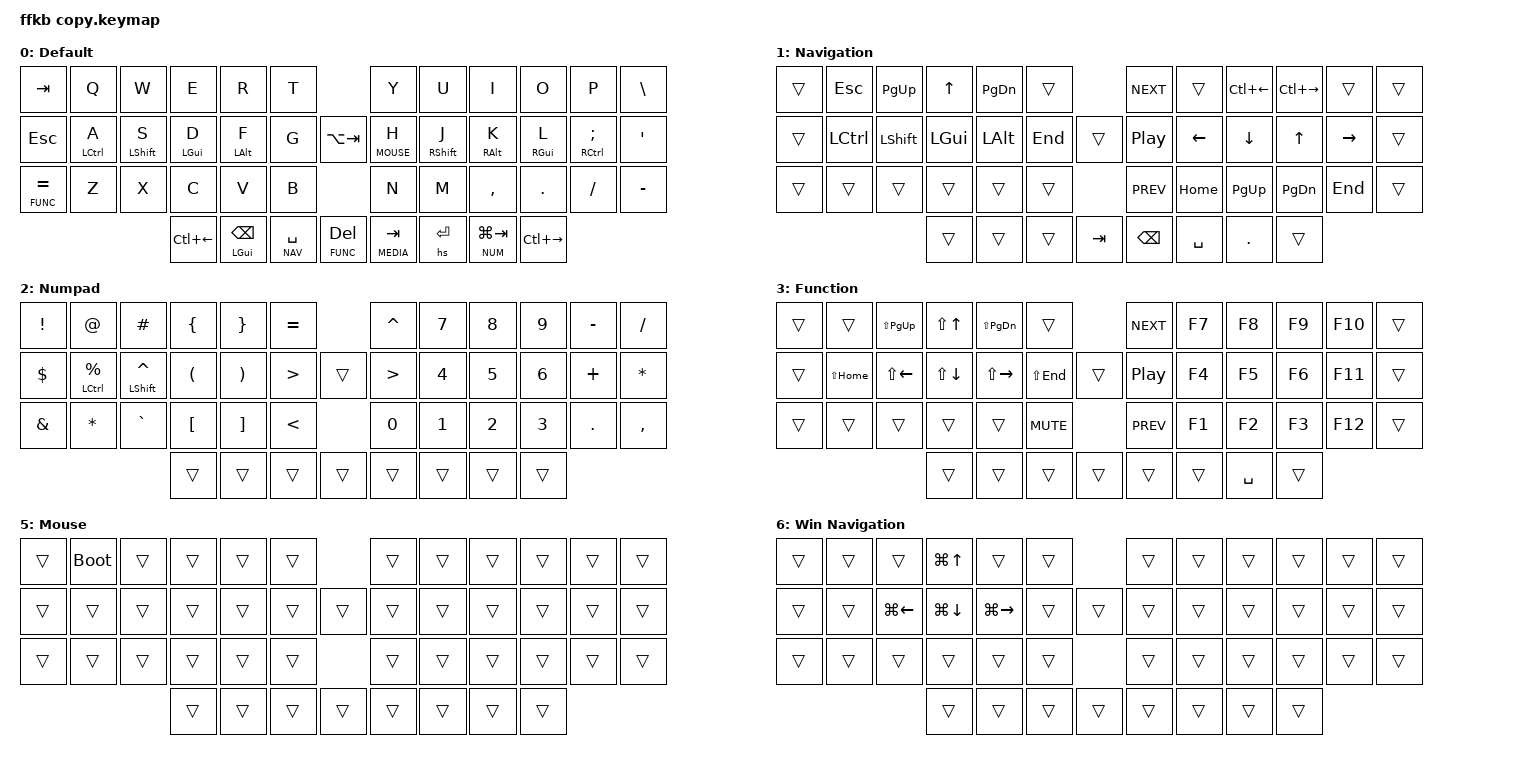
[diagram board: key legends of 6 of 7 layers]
#include <behaviors.dtsi>
#include <dt-bindings/zmk/keys.h>
#include <dt-bindings/zmk/rgb.h>
#include <dt-bindings/zmk/bt.h>
#include <dt-bindings/zmk/ext_power.h>
#include <dt-bindings/zmk/outputs.h>

#define DEFAULT 0
#define NAV     1
#define NUM     2
#define FUNC    3
#define MEDIA   4
#define MOUSE   5
#define WINNAV  6

&caps_word {
    continue-list = <UNDERSCORE MINUS>;
};

/ {
    combos {
        compatible = "zmk,combos";
        combo_undo {
            timeout-ms = <50>;
            key-positions = <26 27>;
            bindings = <&kp LC(Z)>;
        };
        combo_q {
            timeout-ms = <50>;
            key-positions = <27 28>;
            bindings = <&kp Q>;
        };
        combo_semicolon {
            timeout-ms = <50>;
            key-positions = <33 34>;
            bindings = <&kp SEMI>;
        };
    };
};

/ {

    sensors {
        compatible = "zmk,keymap-sensors";
        sensors = <&encoder_1 &encoder_2 &encoder_3>;
    };

    behaviors {
        hm: homerow_mods {
            compatible = "zmk,behavior-hold-tap";
            label = "HOMEROW_MODS";
            #binding-cells = <2>;
            tapping-term-ms = <175>;
            quick_tap_ms = <0>;
            flavor = "balanced";
            bindings = <&kp>, <&kp>;
        };
        hs: homerow_shift {
            compatible = "zmk,behavior-hold-tap";
            label = "HOMEROW_SHIFT";
            #binding-cells = <2>;
            tapping-term-ms = <150>;
            quick_tap_ms = <0>;
            flavor = "balanced";
            bindings = <&kp>, <&kp>;
        };
    };

    keymap {
        compatible = "zmk,keymap";

        default_layer {
            label = "Default";

            sensor-bindings = <&inc_dec_kp LG(Z) LG(Y) &inc_dec_kp C_VOLUME_UP C_VOLUME_DOWN &inc_dec_kp C_VOLUME_UP C_VOLUME_DOWN>;

            bindings = <
    &kp TAB    &kp Q        &kp W        &kp E       &kp R         &kp T                                       &kp Y         &kp U        &kp I  &kp O       &kp P    &kp BSLH
    &kp ESC    &hm LCTL A   &hm LSHIFT S   &hm LGUI D  &hm LALT F  &kp G            &kp LA(TAB)                &lt MOUSE H   &hm RSHIFT J &hm RALT K    &hm RGUI L  &hm RCTL SEMI  &kp SQT
    &lt FUNC EQUAL &kp Z        &kp X        &kp C       &kp V         &kp B                                       &kp N         &kp M        &kp COMMA     &kp DOT     &kp FSLH    &kp MINUS
                                         &kp LC(LEFT)  &hm LGUI BSPC   &lt NAV SPACE  &lt FUNC DEL  &lt MEDIA TAB   &hs RET &lt NUM LG(TAB)      &kp LC(RIGHT)
            >;
        };

        nav_layer {
            label = "Navigation";
            
            sensor-bindings = <&inc_dec_kp LG(Z) LG(Y) &inc_dec_kp C_VOLUME_UP C_VOLUME_DOWN &inc_dec_kp C_VOLUME_UP C_VOLUME_DOWN>;
            
            bindings = <
    &trans     &kp ESC      &kp PG_UP    &kp UP      &kp PG_DN     &trans                                      &kp C_NEXT     &trans       &kp LC(LEFT)        &kp LC(RIGHT)      &trans    &trans
    &trans     &kp LCTL     &kp LSHIFT     &kp LGUI    &kp LALT     &kp END              &trans                 &kp C_PLAY_PAUSE      &kp LEFT       &kp DOWN        &kp UP      &kp RIGHT    &trans
    &trans     &trans       &trans       &trans      &trans        &trans                                      &kp C_PREV     &kp HOME       &kp PG_UP        &kp PG_DN      &kp END      &trans
                                         &trans      &trans        &trans       &kp TAB       &kp BSPC         &kp SPACE     &kp DOT      &trans
            >;
        };

        num_layer {
            label = "Numpad";
            
            sensor-bindings = <&inc_dec_kp LG(Z) LG(Y) &inc_dec_kp C_VOLUME_UP C_VOLUME_DOWN &inc_dec_kp C_VOLUME_UP C_VOLUME_DOWN>;
            
            bindings = <
    &kp EXCL     &kp AT     &kp HASH       &kp LBRC        &kp RBRC         &kp EQUAL                                   &kp CARET     &kp N7          &kp N8     &kp N9   &kp MINUS   &kp FSLH
    &kp DLLR     &hm LCTL PRCNT    &hm LSHIFT CARET     &kp LPAR        &kp RPAR         &kp GT                &trans                &kp GT        &kp N4          &kp N5      &kp N6    &kp PLUS    &kp STAR
    &kp AMPS     &kp STAR     &kp GRAVE    &kp LBKT        &kp RBKT         &kp LT                                  &kp N0        &kp N1        &kp N2       &kp N3      &kp DOT      &kp COMMA
                                         &trans          &trans           &trans       &trans        &trans       &trans        &trans            &trans
            >;
        };

        func_layer {
            label = "Function";

            sensor-bindings = <&inc_dec_kp LG(Z) LG(Y) &inc_dec_kp C_VOLUME_UP C_VOLUME_DOWN &inc_dec_kp C_VOLUME_UP C_VOLUME_DOWN>;
            
            bindings = <
    &trans     &trans       &kp LS(PG_UP) &kp LS(UP)   &kp LS(PG_DN) &trans                                      &kp C_NEXT     &kp F7       &kp F8        &kp F9      &kp F10     &trans
    &trans     &kp LS(HOME) &kp LS(LEFT)  &kp LS(DOWN) &kp LS(RIGHT) &kp LS(END)           &trans                &kp C_PLAY_PAUSE &kp F4       &kp F5        &kp F6      &kp F11     &trans
    &trans     &trans       &trans        &trans       &trans        &kp C_MUTE                                  &kp C_PREV     &kp F1       &kp F2        &kp F3      &kp F12     &trans
                                          &trans       &trans        &trans        &trans         &trans         &trans           &kp SPACE    &trans
            >;
        };

        media_layer {
            label = "Media";
            
            sensor-bindings = <&inc_dec_kp LG(Z) LG(Y) &inc_dec_kp C_VOLUME_UP C_VOLUME_DOWN &inc_dec_kp C_VOLUME_UP C_VOLUME_DOWN>;
            
            bindings = <
    &rgb_ug RGB_COLOR_HSB(0,0,100)         &rgb_ug RGB_TOG  &rgb_ug RGB_EFR  &rgb_ug RGB_EFF &trans            &trans                            &trans             &bt BT_PRV        &bt BT_NXT         &trans         &trans          &trans
    &rgb_ug RGB_COLOR_HSB(224,100,100)     &trans           &rgb_ug RGB_HUI  &rgb_ug RGB_SAI &rgb_ug RGB_BRI   &rgb_ug RGB_SPI      &trans       &bt BT_CLR         &bt BT_SEL 0      &bt BT_SEL 1       &bt BT_SEL 2   &bt BT_SEL 3    &trans
    &rgb_ug RGB_COLOR_HSB(278,100,100)     &trans           &rgb_ug RGB_HUD  &rgb_ug RGB_SAD &rgb_ug RGB_BRD   &rgb_ug RGB_SPD                   &ext_power EP_TOG  &ext_power EP_ON  &ext_power EP_OFF  &out OUT_USB   &out OUT_BLE    &trans
                                                                            &trans          &trans            &trans        &trans         &trans         &trans           &trans     &trans
            >;
        };

        mouse_layer {
            label = "Mouse";
            
            sensor-bindings = <&inc_dec_kp LG(Z) LG(Y) &inc_dec_kp C_VOLUME_UP C_VOLUME_DOWN &inc_dec_kp C_VOLUME_UP C_VOLUME_DOWN>;
            
            bindings = <
    &trans     &bootloader &trans      &trans      &trans      &trans                                           &trans      &trans      &trans      &trans      &trans      &trans
    &trans     &trans      &trans      &trans      &trans      &trans                   &trans                  &trans      &trans      &trans      &trans      &trans      &trans
    &trans     &trans      &trans      &trans      &trans      &trans                                           &trans      &trans      &trans      &trans      &trans      &trans
                                         &trans      &trans        &trans        &trans         &trans          &trans      &trans      &trans
            >;
        };

        winnav_layer {
            label = "Win Navigation";
            
            sensor-bindings = <&inc_dec_kp LG(Z) LG(Y) &inc_dec_kp C_VOLUME_UP C_VOLUME_DOWN &inc_dec_kp C_VOLUME_UP C_VOLUME_DOWN>;
            
            bindings = <
    &trans     &trans       &trans       &kp LG(UP)   &trans        &trans                                      &trans      &trans      &trans      &trans      &trans      &trans
    &trans     &trans       &kp LG(LEFT) &kp LG(DOWN) &kp LG(RIGHT) &trans                &trans                &trans      &trans      &trans      &trans      &trans      &trans
    &trans     &trans       &trans       &trans       &trans        &trans                                      &trans      &trans      &trans      &trans      &trans      &trans
                                         &trans       &trans        &trans        &trans         &trans         &trans        &trans       &trans
            >;
        };
    };
};
